VERSION ""

NS_ :

BS_:

BU_: XXX EPS ESP SCM

BO_ 37 STEER_ANGLE_SENSOR: 32 XXX
 SG_ STEER_ANGLE : 3|12@0- (1.5,0) [-500|500] "deg" XXX
 SG_ STEER_FRACTION : 39|4@0- (0.1,0) [-0.7|0.7] "deg" XXX
 SG_ STEER_RATE : 35|12@0- (1,0) [-2000|2000] "deg/s" XXX

BO_ 48 TSS3_EPS_TELEMETRY: 32 EPS
 SG_ DRIVER_TORQUE_INVALID : 48|1@0+ (1,0) [0|1] "" XXX
 SG_ STEERING_WHEEL_TORQUE_COARSE : 71|8@0- (0.1,0) [-12.8|12.7] "Nm" XXX
 SG_ STEERING_WHEEL_TORQUE_FINE : 139|4@0- (0.01,0) [-0.08|0.07] "Nm" XXX

BO_ 254 TSS3_CRUISE_SWITCH: 32 XXX
 SG_ MAIN_BUTTON : 58|1@0+ (1,0) [0|1] "" XXX
 SG_ RES_BUTTON : 31|1@0+ (1,0) [0|1] "" XXX
 SG_ RES_BUTTON_MIRROR_N : 55|1@0+ (1,0) [0|1] "" XXX
 SG_ SET_BUTTON : 39|1@0+ (1,0) [0|1] "" XXX
 SG_ SET_BUTTON_MIRROR_N : 62|1@0+ (1,0) [0|1] "" XXX
 SG_ CANCEL_BUTTON : 38|1@0+ (1,0) [0|1] "" XXX
 SG_ CANCEL_BUTTON_MIRROR_N : 61|1@0+ (1,0) [0|1] "" XXX

BO_ 138 TSS3_LATERAL_REQUEST: 32 XXX
 SG_ CRUISE_OPERATING_LATCH : 27|1@0+ (1,0) [0|1] "" XXX
 SG_ CRUISE_SUBSTATE_2 : 63|8@0+ (1,0) [0|255] "" XXX
 SG_ SET_SPEED : 87|8@0+ (1,0) [0|255] "km/h" XXX

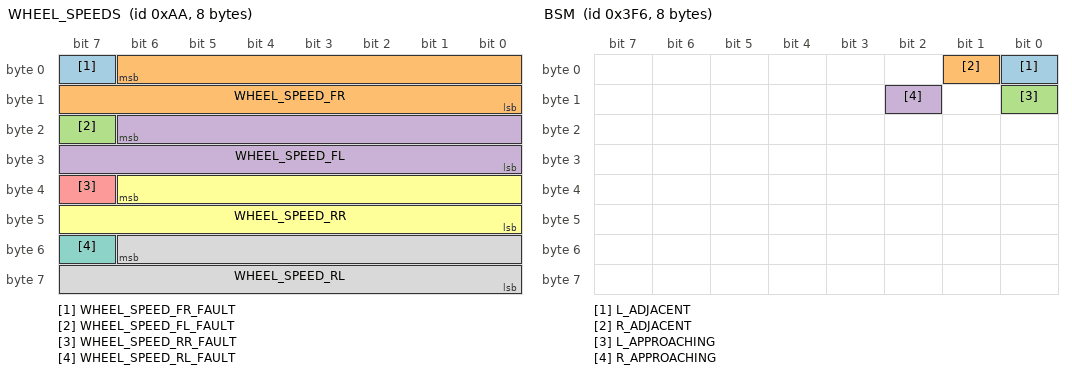
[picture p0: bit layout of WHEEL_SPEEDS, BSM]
BO_ 170 WHEEL_SPEEDS: 8 XXX
 SG_ WHEEL_SPEED_FR_FAULT : 7|1@0+ (1,0) [0|1] "" XXX
 SG_ WHEEL_SPEED_FR : 6|15@0+ (0.01,-67.67) [-67.67|260] "km/h" XXX
 SG_ WHEEL_SPEED_FL_FAULT : 23|1@0+ (1,0) [0|1] "" XXX
 SG_ WHEEL_SPEED_FL : 22|15@0+ (0.01,-67.67) [-67.67|260] "km/h" XXX
 SG_ WHEEL_SPEED_RR_FAULT : 39|1@0+ (1,0) [0|1] "" XXX
 SG_ WHEEL_SPEED_RR : 38|15@0+ (0.01,-67.67) [-67.67|260] "km/h" XXX
 SG_ WHEEL_SPEED_RL_FAULT : 55|1@0+ (1,0) [0|1] "" XXX
 SG_ WHEEL_SPEED_RL : 54|15@0+ (0.01,-67.67) [-67.67|260] "km/h" XXX

BO_ 257 BRAKE_MODULE: 8 XXX
 SG_ BRAKE_PRESSED : 3|1@0+ (1,0) [0|1] "" XXX

BO_ 278 GAS_PEDAL: 8 XXX
 SG_ GAS_PEDAL_USER : 15|8@0+ (0.005,0) [0|1.275] "" XXX

BO_ 295 GEAR_PACKET_HYBRID: 8 XXX
 SG_ GEAR : 47|4@0+ (1,0) [0|15] "" XXX

BO_ 593 TSS3_CRUISE_DISPLAY: 8 XXX
 SG_ CRUISE_MAIN_STATE : 12|1@0+ (1,0) [0|1] "" XXX
 SG_ UI_SET_SPEED : 23|8@0+ (1,0) [0|255] "" XXX

BO_ 951 ESP_CONTROL: 8 ESP
 SG_ TC_DISABLED : 13|1@0+ (1,0) [0|1] "" XXX
 SG_ BRAKE_HOLD_ACTIVE : 36|1@0+ (1,0) [0|1] "" XXX

BO_ 1014 BSM: 8 XXX
 SG_ L_ADJACENT : 0|1@0+ (1,0) [0|1] "" XXX
 SG_ R_ADJACENT : 1|1@0+ (1,0) [0|1] "" XXX
 SG_ L_APPROACHING : 8|1@0+ (1,0) [0|1] "" XXX
 SG_ R_APPROACHING : 10|1@0+ (1,0) [0|1] "" XXX

BO_ 1310 TSS3_READY_STATUS: 8 XXX
 SG_ READY_STATUS : 7|1@0+ (1,0) [0|1] "" XXX

BO_ 1552 BODY_CONTROL_STATE_2: 8 XXX
 SG_ UI_SPEED : 23|8@0+ (1,0) [0|255] "km/h" XXX
 SG_ UNITS : 63|3@0+ (1,0) [0|4] "" XXX

BO_ 1556 BLINKERS_STATE: 8 XXX
 SG_ TURN_SIGNALS : 29|2@0+ (1,0) [0|3] "" XXX

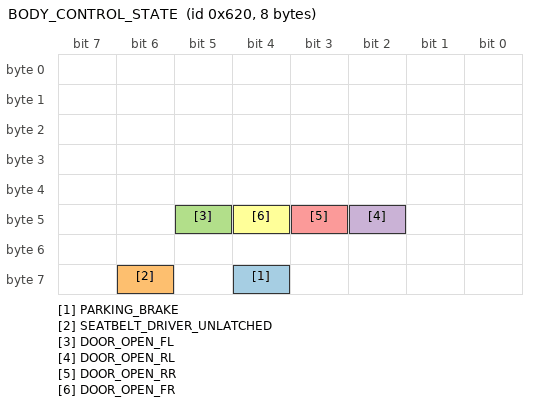
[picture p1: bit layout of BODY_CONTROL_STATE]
BO_ 1568 BODY_CONTROL_STATE: 8 XXX
 SG_ PARKING_BRAKE : 60|1@0+ (1,0) [0|1] "" XXX
 SG_ SEATBELT_DRIVER_UNLATCHED : 62|1@0+ (1,0) [0|1] "" XXX
 SG_ DOOR_OPEN_FL : 45|1@0+ (1,0) [0|1] "" XXX
 SG_ DOOR_OPEN_RL : 42|1@0+ (1,0) [0|1] "" XXX
 SG_ DOOR_OPEN_RR : 43|1@0+ (1,0) [0|1] "" XXX
 SG_ DOOR_OPEN_FR : 44|1@0+ (1,0) [0|1] "" XXX

BO_ 1570 LIGHT_STALK: 8 SCM
 SG_ AUTO_HIGH_BEAM : 37|1@0+ (1,0) [0|1] "" XXX

VAL_ 295 GEAR 0 "P" 1 "R" 2 "N" 3 "D" 4 "B" ;
VAL_ 1556 TURN_SIGNALS 3 "hazard" 2 "right" 1 "left" 0 "none";
